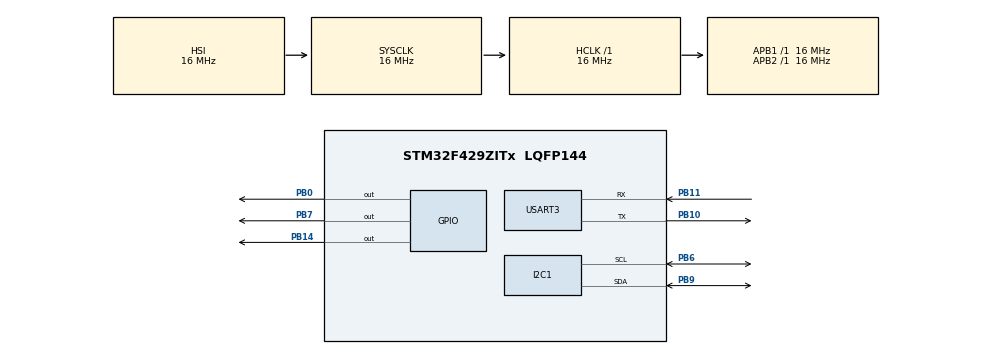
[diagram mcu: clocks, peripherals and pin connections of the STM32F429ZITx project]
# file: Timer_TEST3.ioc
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Mcu.Family=STM32F4
Mcu.Name=STM32F429ZITx
Mcu.Package=LQFP144
NVIC.PriorityGroup=NVIC_PRIORITYGROUP_4
NVIC.TIM2_IRQn=true\:0\:0\:false\:true\:true\:4\:true\:true\:true
NVIC.TIM3_IRQn=true\:0\:0\:false\:true\:true\:3\:true\:true\:true
NVIC.TIM4_IRQn=true\:0\:0\:false\:true\:true\:2\:true\:true\:true
NVIC.USART3_IRQn=true\:0\:0\:false\:true\:true\:1\:true\:true\:true
PB0.Signal=GPIO_Output
PB10.Mode=Asynchronous
PB10.Signal=USART3_TX
PB11.Mode=Asynchronous
PB11.Signal=USART3_RX
PB14.Signal=GPIO_Output
PB6.Mode=I2C
PB6.Signal=I2C1_SCL
PB7.Signal=GPIO_Output
PB9.Mode=I2C
PB9.Signal=I2C1_SDA
ProjectManager.HeapSize=0x200
ProjectManager.StackSize=0x400
ProjectManager.TargetToolchain=STM32CubeIDE
RCC.AHBFreq_Value=16000000
RCC.APB1Freq_Value=16000000
RCC.APB2Freq_Value=16000000
RCC.CortexFreq_Value=16000000
RCC.HSE_VALUE=25000000
RCC.HSI_VALUE=16000000
RCC.LSE_VALUE=32768
RCC.SYSCLKFreq_VALUE=16000000
RCC.VCOOutputFreq_Value=192000000
TIM2.Period=1000-1
TIM2.Prescaler=1600-1
TIM3.Channel-PWM\ Generation3\ CH3=TIM_CHANNEL_3
TIM3.Period=5000-1
TIM3.Prescaler=1600-1
TIM4.Period=10000-1
TIM4.Prescaler=1600-1
USART3.VirtualMode=VM_ASYNC
VP_TIM2_VS_ClockSourceINT.Mode=Internal
VP_TIM3_VS_ClockSourceINT.Mode=Internal
VP_TIM4_VS_ClockSourceINT.Mode=Internal
board=custom

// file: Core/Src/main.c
/* USER CODE BEGIN Header */
/**
  ******************************************************************************
  * @file           : main.c
  * @brief          : Main program body
  ******************************************************************************
  * @attention
  *
  * Copyright (c) 2023 STMicroelectronics.
  * All rights reserved.
  *
  * This software is licensed under terms that can be found in the LICENSE file
  * in the root directory of this software component.
  * If no LICENSE file comes with this software, it is provided AS-IS.
  *
  ******************************************************************************
  */
/* USER CODE END Header */
#include "main.h"

I2C_HandleTypeDef hi2c1;

TIM_HandleTypeDef htim2;
TIM_HandleTypeDef htim3;
TIM_HandleTypeDef htim4;

UART_HandleTypeDef huart3;

void SystemClock_Config(void);
static void MX_GPIO_Init(void);
static void MX_TIM2_Init(void);
static void MX_TIM3_Init(void);
static void MX_TIM4_Init(void);
static void MX_I2C1_Init(void);
static void MX_USART3_UART_Init(void);
static void MX_NVIC_Init(void);

int main(void)
{

  /* MCU Configuration--------------------------------------------------------*/

  /* Reset of all peripherals, Initializes the Flash interface and the Systick. */
  HAL_Init();

  /* Configure the system clock */
  SystemClock_Config();

  /* Initialize all configured peripherals */
  MX_GPIO_Init();
  MX_TIM2_Init();
  MX_TIM3_Init();
  MX_TIM4_Init();
  MX_I2C1_Init();
  MX_USART3_UART_Init();

  /* Initialize interrupts */
  MX_NVIC_Init();
  /* USER CODE BEGIN 2 */
  //???��머의 ?��?��?��?���? 반복 ?��?��?�� ?�� ?��?���? 메인?��?�� 최초 ?��번�? ?��출이 ?��?��?��.
  HAL_TIM_Base_Start_IT(&htim2);
  HAL_TIM_Base_Start_IT(&htim3);
  HAL_TIM_Base_Start_IT(&htim4);
  /* USER CODE END 2 */

  /* Infinite loop */
  while (1)
  {

  }
}

void SystemClock_Config(void)
{
  RCC_OscInitTypeDef RCC_OscInitStruct = {0};
  RCC_ClkInitTypeDef RCC_ClkInitStruct = {0};

  /** Configure the main internal regulator output voltage
  */
  __HAL_RCC_PWR_CLK_ENABLE();
  __HAL_PWR_VOLTAGESCALING_CONFIG(PWR_REGULATOR_VOLTAGE_SCALE3);

  /** Initializes the RCC Oscillators according to the specified parameters
  * in the RCC_OscInitTypeDef structure.
  */
  RCC_OscInitStruct.OscillatorType = RCC_OSCILLATORTYPE_HSI;
  RCC_OscInitStruct.HSIState = RCC_HSI_ON;
  RCC_OscInitStruct.HSICalibrationValue = RCC_HSICALIBRATION_DEFAULT;
  RCC_OscInitStruct.PLL.PLLState = RCC_PLL_NONE;
  if (HAL_RCC_OscConfig(&RCC_OscInitStruct) != HAL_OK)
  {
    Error_Handler();
  }

  /** Initializes the CPU, AHB and APB buses clocks
  */
  RCC_ClkInitStruct.ClockType = RCC_CLOCKTYPE_HCLK|RCC_CLOCKTYPE_SYSCLK
                              |RCC_CLOCKTYPE_PCLK1|RCC_CLOCKTYPE_PCLK2;
  RCC_ClkInitStruct.SYSCLKSource = RCC_SYSCLKSOURCE_HSI;
  RCC_ClkInitStruct.AHBCLKDivider = RCC_SYSCLK_DIV1;
  RCC_ClkInitStruct.APB1CLKDivider = RCC_HCLK_DIV1;
  RCC_ClkInitStruct.APB2CLKDivider = RCC_HCLK_DIV1;

  if (HAL_RCC_ClockConfig(&RCC_ClkInitStruct, FLASH_LATENCY_0) != HAL_OK)
  {
    Error_Handler();
  }
}

/**
  * @brief NVIC Configuration.
  * @retval None
  */
static void MX_NVIC_Init(void)
{
  /* USART3_IRQn interrupt configuration */
  HAL_NVIC_SetPriority(USART3_IRQn, 0, 0);
  HAL_NVIC_EnableIRQ(USART3_IRQn);
  /* TIM4_IRQn interrupt configuration */
  HAL_NVIC_SetPriority(TIM4_IRQn, 0, 0);
  HAL_NVIC_EnableIRQ(TIM4_IRQn);
  /* TIM3_IRQn interrupt configuration */
  HAL_NVIC_SetPriority(TIM3_IRQn, 0, 0);
  HAL_NVIC_EnableIRQ(TIM3_IRQn);
  /* TIM2_IRQn interrupt configuration */
  HAL_NVIC_SetPriority(TIM2_IRQn, 0, 0);
  HAL_NVIC_EnableIRQ(TIM2_IRQn);
}

static void MX_I2C1_Init(void)
{

  hi2c1.Instance = I2C1;
  hi2c1.Init.ClockSpeed = 100000;
  hi2c1.Init.DutyCycle = I2C_DUTYCYCLE_2;
  hi2c1.Init.OwnAddress1 = 0;
  hi2c1.Init.AddressingMode = I2C_ADDRESSINGMODE_7BIT;
  hi2c1.Init.DualAddressMode = I2C_DUALADDRESS_DISABLE;
  hi2c1.Init.OwnAddress2 = 0;
  hi2c1.Init.GeneralCallMode = I2C_GENERALCALL_DISABLE;
  hi2c1.Init.NoStretchMode = I2C_NOSTRETCH_DISABLE;
  if (HAL_I2C_Init(&hi2c1) != HAL_OK)
  {
    Error_Handler();
  }

  /** Configure Analogue filter
  */
  if (HAL_I2CEx_ConfigAnalogFilter(&hi2c1, I2C_ANALOGFILTER_ENABLE) != HAL_OK)
  {
    Error_Handler();
  }

  /** Configure Digital filter
  */
  if (HAL_I2CEx_ConfigDigitalFilter(&hi2c1, 0) != HAL_OK)
  {
    Error_Handler();
  }

}

static void MX_TIM2_Init(void)
{

  TIM_ClockConfigTypeDef sClockSourceConfig = {0};
  TIM_MasterConfigTypeDef sMasterConfig = {0};

  htim2.Instance = TIM2;
  htim2.Init.Prescaler = 1600-1;
  htim2.Init.CounterMode = TIM_COUNTERMODE_UP;
  htim2.Init.Period = 1000-1;
  htim2.Init.ClockDivision = TIM_CLOCKDIVISION_DIV1;
  htim2.Init.AutoReloadPreload = TIM_AUTORELOAD_PRELOAD_DISABLE;
  if (HAL_TIM_Base_Init(&htim2) != HAL_OK)
  {
    Error_Handler();
  }
  sClockSourceConfig.ClockSource = TIM_CLOCKSOURCE_INTERNAL;
  if (HAL_TIM_ConfigClockSource(&htim2, &sClockSourceConfig) != HAL_OK)
  {
    Error_Handler();
  }
  sMasterConfig.MasterOutputTrigger = TIM_TRGO_RESET;
  sMasterConfig.MasterSlaveMode = TIM_MASTERSLAVEMODE_DISABLE;
  if (HAL_TIMEx_MasterConfigSynchronization(&htim2, &sMasterConfig) != HAL_OK)
  {
    Error_Handler();
  }

}

static void MX_TIM3_Init(void)
{

  TIM_ClockConfigTypeDef sClockSourceConfig = {0};
  TIM_MasterConfigTypeDef sMasterConfig = {0};

  htim3.Instance = TIM3;
  htim3.Init.Prescaler = 1600-1;
  htim3.Init.CounterMode = TIM_COUNTERMODE_UP;
  htim3.Init.Period = 5000-1;
  htim3.Init.ClockDivision = TIM_CLOCKDIVISION_DIV1;
  htim3.Init.AutoReloadPreload = TIM_AUTORELOAD_PRELOAD_DISABLE;
  if (HAL_TIM_Base_Init(&htim3) != HAL_OK)
  {
    Error_Handler();
  }
  sClockSourceConfig.ClockSource = TIM_CLOCKSOURCE_INTERNAL;
  if (HAL_TIM_ConfigClockSource(&htim3, &sClockSourceConfig) != HAL_OK)
  {
    Error_Handler();
  }
  sMasterConfig.MasterOutputTrigger = TIM_TRGO_RESET;
  sMasterConfig.MasterSlaveMode = TIM_MASTERSLAVEMODE_DISABLE;
  if (HAL_TIMEx_MasterConfigSynchronization(&htim3, &sMasterConfig) != HAL_OK)
  {
    Error_Handler();
  }

}

static void MX_TIM4_Init(void)
{

  TIM_ClockConfigTypeDef sClockSourceConfig = {0};
  TIM_MasterConfigTypeDef sMasterConfig = {0};

  htim4.Instance = TIM4;
  htim4.Init.Prescaler = 1600-1;
  htim4.Init.CounterMode = TIM_COUNTERMODE_UP;
  htim4.Init.Period = 10000-1;
  htim4.Init.ClockDivision = TIM_CLOCKDIVISION_DIV1;
  htim4.Init.AutoReloadPreload = TIM_AUTORELOAD_PRELOAD_DISABLE;
  if (HAL_TIM_Base_Init(&htim4) != HAL_OK)
  {
    Error_Handler();
  }
  sClockSourceConfig.ClockSource = TIM_CLOCKSOURCE_INTERNAL;
  if (HAL_TIM_ConfigClockSource(&htim4, &sClockSourceConfig) != HAL_OK)
  {
    Error_Handler();
  }
  sMasterConfig.MasterOutputTrigger = TIM_TRGO_RESET;
  sMasterConfig.MasterSlaveMode = TIM_MASTERSLAVEMODE_DISABLE;
  if (HAL_TIMEx_MasterConfigSynchronization(&htim4, &sMasterConfig) != HAL_OK)
  {
    Error_Handler();
  }

}

static void MX_USART3_UART_Init(void)
{

  huart3.Instance = USART3;
  huart3.Init.BaudRate = 115200;
  huart3.Init.WordLength = UART_WORDLENGTH_8B;
  huart3.Init.StopBits = UART_STOPBITS_1;
  huart3.Init.Parity = UART_PARITY_NONE;
  huart3.Init.Mode = UART_MODE_TX_RX;
  huart3.Init.HwFlowCtl = UART_HWCONTROL_NONE;
  huart3.Init.OverSampling = UART_OVERSAMPLING_16;
  if (HAL_UART_Init(&huart3) != HAL_OK)
  {
    Error_Handler();
  }

}

static void MX_GPIO_Init(void)
{
  GPIO_InitTypeDef GPIO_InitStruct = {0};

  /* GPIO Ports Clock Enable */
  __HAL_RCC_GPIOB_CLK_ENABLE();

  /*Configure GPIO pin Output Level */
  HAL_GPIO_WritePin(GPIOB, GPIO_PIN_0|GPIO_PIN_14|GPIO_PIN_7, GPIO_PIN_RESET);

  /*Configure GPIO pins : PB0 PB14 PB7 */
  GPIO_InitStruct.Pin = GPIO_PIN_0|GPIO_PIN_14|GPIO_PIN_7;
  GPIO_InitStruct.Mode = GPIO_MODE_OUTPUT_PP;
  GPIO_InitStruct.Pull = GPIO_NOPULL;
  GPIO_InitStruct.Speed = GPIO_SPEED_FREQ_LOW;
  HAL_GPIO_Init(GPIOB, &GPIO_InitStruct);

}

/* USER CODE BEGIN 4 */

void HAL_TIM_PeriodElapsedCallback(TIM_HandleTypeDef *htim)
{
	if(htim -> Instance == htim2.Instance) //1000 / 10000 => 0.1�?
	{
		HAL_GPIO_TogglePin(GPIOB, GPIO_PIN_14);
	}
	if(htim -> Instance == htim3.Instance) //5000 / 10000 => 0.5�?
	{
		HAL_GPIO_TogglePin(GPIOB, GPIO_PIN_7);
	}
	if(htim -> Instance == htim4.Instance) //10000 / 10000 => 1�?
	{
		HAL_GPIO_TogglePin(GPIOB, GPIO_PIN_0);
	}
}
/* USER CODE END 4 */

void Error_Handler(void)
{
  __disable_irq();
  while (1)
  {
  }
}
